VERSION ""

NS_ :

BS_:

BU_:

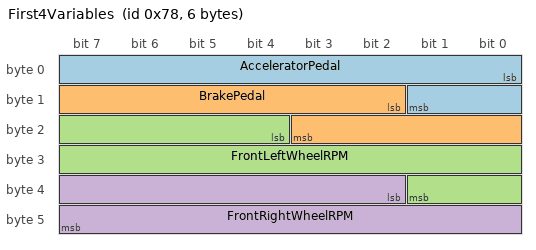
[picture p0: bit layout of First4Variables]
BO_ 120 First4Variables: 6 Vector__XXX
	SG_ AcceleratorPedal : 0|10@1+ (1,0) [0|1023] "" Vector__XXX
	SG_ BrakePedal : 10|10@1+ (1,0) [0|1023] "" Vector__XXX
	SG_ FrontLeftWheelRPM : 20|14@1+ (1,0) [0|6000] "RPM" Vector__XXX
	SG_ FrontRightWheelRPM : 34|14@1+ (1,0) [0|6000] "RPM" Vector__XXX

BO_ 121 Last2Variables: 4 Vector__XXX
	SG_ RearLeftWheelRPM : 0|16@1+ (1,0) [0|6000] "RPM" Vector__XXX
	SG_ RearRightWheelRPM : 16|16@1+ (1,0) [0|6000] "RPM" Vector__XXX

BA_DEF_ BO_  "VFrameFormat" ENUM  "StandardCAN","ExtendedCAN","reserved","J1939PG";
BA_DEF_  "DatabaseVersion" STRING ;
BA_DEF_  "BusType" STRING ;
BA_DEF_  "ProtocolType" STRING ;
BA_DEF_  "DatabaseCompiler" STRING ;
BA_DEF_DEF_  "VFrameFormat" "J1939PG";
BA_DEF_DEF_  "DatabaseVersion" "DEMO PLUS";
BA_DEF_DEF_  "BusType" "";
BA_DEF_DEF_  "ProtocolType" "";
BA_DEF_DEF_  "DatabaseCompiler" "";
BA_ "ProtocolType" "J1939";
BA_ "BusType" "CAN";
BA_ "DatabaseCompiler" "CSS ELECTRONICS (WWW.CSSELECTRONICS.COM)";
BA_ "DatabaseVersion" "1.0.0";
